# G32R502 register map
Vendor: Geehy Semiconductor Co., Ltd.; Series: G32R5; File version: 1.0
CPU: CM52 r0p1, little endian, MPU, FPU, DSP, VTOR, 4 interrupt priority bits
Registers are 32-bit, read-write, reset 0x0 unless marked. A register's access mark holds for its fields unless they carry their own. Offsets are from the block's base; [hi:lo] are bit positions; {n}, {i} and the like mark numbered series.

## GPIODATA — GPIO DATA Registers
Base 0x40030800
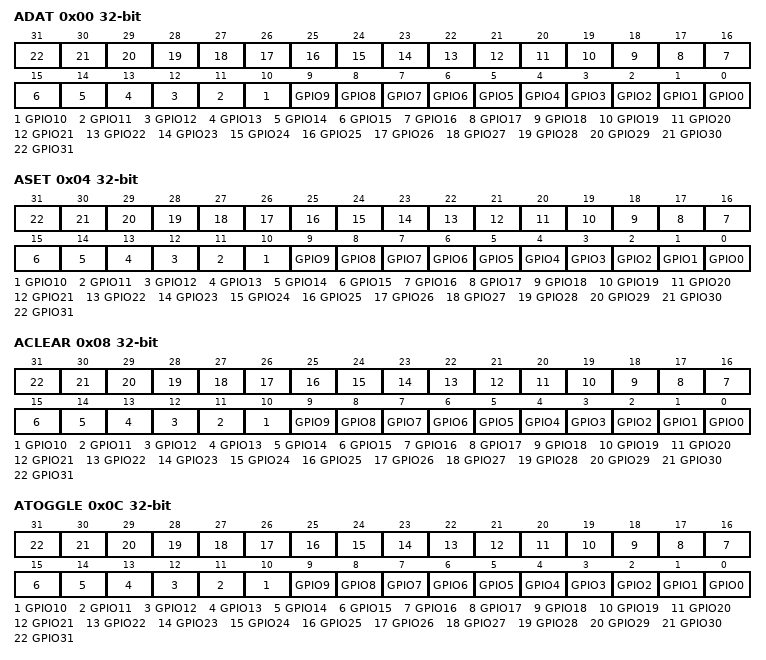
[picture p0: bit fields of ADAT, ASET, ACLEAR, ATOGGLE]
0x00 ADAT — GPIO A Data Register (GPIO0 to GPIO31)
  [n] GPIO{n} (n=0..31) — GPIO{n} Read/Write Data Bit
0x04 ASET — GPIO A Output Set (GPIO0 to GPIO31)
  [n] GPIO{n} (n=0..31) — Set the GPIO{n} output data latch
0x08 ACLEAR — GPIO A Output Clear (GPIO0 to GPIO31)
  [n] GPIO{n} (n=0..31) — Clear the GPIO{n} output data latch
0x0C ATOGGLE — GPIO A Output Toggle (GPIO0 to GPIO31)
  [n] GPIO{n} (n=0..31) — Toggle the GPIO{n} output data latch
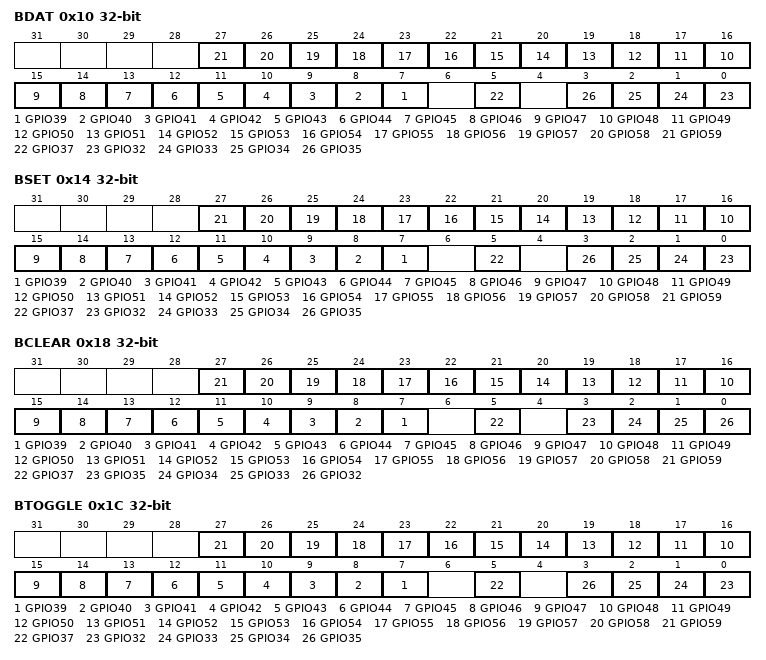
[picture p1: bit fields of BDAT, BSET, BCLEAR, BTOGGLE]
0x10 BDAT — GPIO B Data Register (GPIO32 to GPIO64)
  [n-32] GPIO{n} (n=39..59) — GPIO{n} Read/Write Data Bit
  [5] GPIO37 — GPIO37 Read/Write Data Bit
  [n-32] GPIO{n} (n=32..35) — GPIO{n} Read/Write Data Bit
0x14 BSET — GPIO B Output Set (GPIO32 to GPIO64)
  [n-32] GPIO{n} (n=39..59) — Set the GPIO{n} output data latch
  [5] GPIO37 — Set the GPIO37 output data latch
  [n-32] GPIO{n} (n=32..35) — Set the GPIO{n} output data latch
0x18 BCLEAR — GPIO B Output Clear (GPIO32 to GPIO64)
  [n-32] GPIO{n} (n=39..59) — Clear the GPIO{n} output data latch
  [5] GPIO37 — Clear the GPIO37 output data latch
  [3] GPIO35 — Clear the GPIO32 output data latch
  [2] GPIO34 — Clear the GPIO34 outpu data latch
  [1] GPIO33 — Clear the GPIO33 output data latch
  [0] GPIO32 — Clear the GPIO32 output data latch
0x1C BTOGGLE — GPIO B Output Toggle (GPIO32 to GPIO64)
  [n-32] GPIO{n} (n=39..59) — Toggle the GPIO{n} output data latch
  [5] GPIO37 — Toggle the GPIO37 output data latch
  [n-32] GPIO{n} (n=32..35) — Toggle the GPIO{n} output data latch
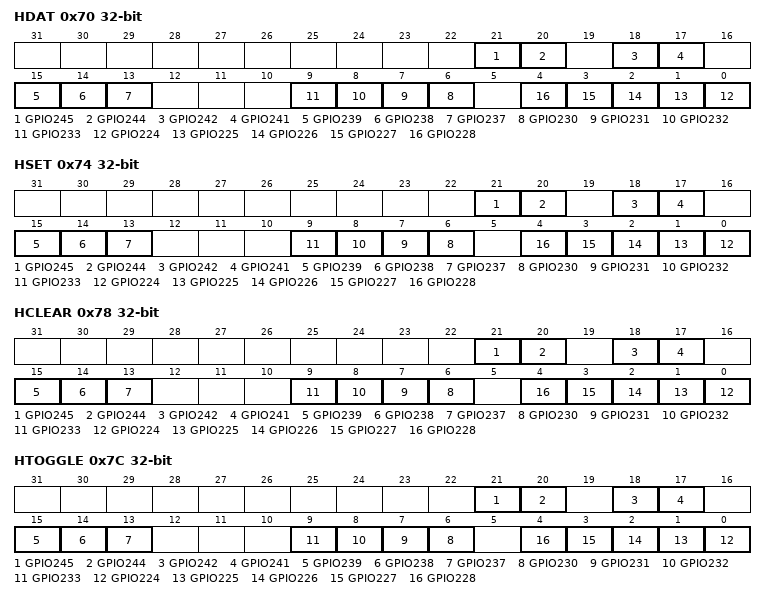
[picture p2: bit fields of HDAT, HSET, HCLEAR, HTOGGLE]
0x70 HDAT — GPIO H Data Register (GPIO224 to GPIO245)
  [21] GPIO245 — GPIO245 Read/Write Data Bit
  [20] GPIO244 — GPIO244 Read/Write Data Bit
  [18] GPIO242 — GPIO242 Read/Write Data Bit
  [17] GPIO241 — GPIO241 Read/Write Data Bit
  [15] GPIO239 — GPIO239 Read/Write Data Bit
  [14] GPIO238 — GPIO238 Read/Write Data Bit
  [13] GPIO237 — GPIO237 Read/Write Data Bit
  [n-224] GPIO{n} (n=230..233) — GPIO{n} Read/Write Data Bit
  [n-224] GPIO{n} (n=224..228) — GPIO{n} Read/Write Data Bit
0x74 HSET — GPIO H Output Set (GPIO224 to GPIO245)
  [21] GPIO245 — Set the GPIO245 output data latch
  [20] GPIO244 — Set the GPIO244 output data latch
  [18] GPIO242 — Set the GPIO242 output data latch
  [17] GPIO241 — Set the GPIO241 output data latch
  [15] GPIO239 — Set the GPIO239 output data latch
  [14] GPIO238 — Set the GPIO238 output data latch
  [13] GPIO237 — Set the GPIO237 output data latch
  [n-224] GPIO{n} (n=230..233) — Set the GPIO{n} output data latch
  [n-224] GPIO{n} (n=224..228) — Set the GPIO{n} output data latch
0x78 HCLEAR — GPIO H Output Clear (GPIO224 to GPIO245)
  [21] GPIO245 — Clear the GPIO245 output data latch
  [20] GPIO244 — Clear the GPIO244 output data latch
  [18] GPIO242 — Clear the GPIO242 output data latch
  [17] GPIO241 — Clear the GPIO241 output data latch
  [15] GPIO239 — Clear the GPIO239 output data latch
  [14] GPIO238 — Clear the GPIO238 output data latch
  [13] GPIO237 — Clear the GPIO237 output data latch
  [n-224] GPIO{n} (n=230..233) — Clear the GPIO{n} output data latch
  [n-224] GPIO{n} (n=224..228) — Clear the GPIO{n} output data latch
0x7C HTOGGLE — GPIO H Output Toggle (GPIO224 to GPIO245)
  [21] GPIO245 — Toggle the GPIO245 output data latch
  [20] GPIO244 — Toggle the GPIO244 output data latch
  [18] GPIO242 — Toggle the GPIO242 output data latch
  [17] GPIO241 — Toggle the GPIO241 output data latch
  [15] GPIO239 — Toggle the GPIO239 output data latch
  [14] GPIO238 — Toggle the GPIO238 output data latch
  [13] GPIO237 — Toggle the GPIO237 output data latch
  [n-224] GPIO{n} (n=230..233) — Toggle the GPIO{n} output data latch
  [n-224] GPIO{n} (n=224..228) — Toggle the GPIO{n} output data latch
